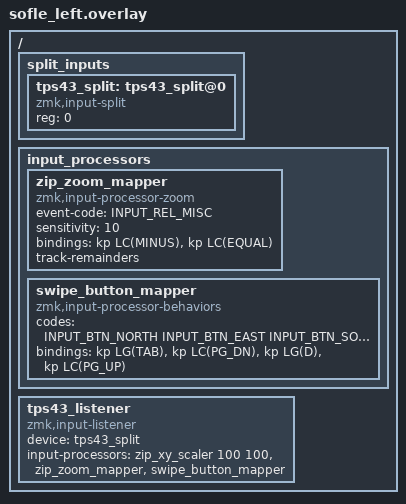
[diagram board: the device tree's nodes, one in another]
/*
 * Central-side (left) half of the Azoteq TPS43 trackpad support.
 *
 * The trackpad itself lives on the right (peripheral) half - see
 * sofle_right.overlay. Its raw input events are relayed over the split
 * link via zmk,input-split; this file is the central-side proxy plus
 * the listener that turns those events into mouse movement, scroll,
 * pinch-zoom and swipe behaviors.
 */

#include <input/processors.dtsi>
#include <dt-bindings/input/input-event-codes.h>
#include <dt-bindings/zmk/keys.h>
#include <behaviors.dtsi>

// Comment out for macOS-style shortcuts (Cmd), leave defined for
// Windows/Linux-style shortcuts (Ctrl).
#define TRACKPAD_WIN_MODE

/ {
    split_inputs {
        #address-cells = <1>;
        #size-cells = <0>;

        tps43_split: tps43_split@0 {
            compatible = "zmk,input-split";
            reg = <0>;
            /* No `device` here - the trackpad lives on the peripheral
             * (right) half; this node is just the central-side proxy
             * that receives its relayed events. */
        };
    };

    input_processors {
        zip_zoom_mapper: zip_zoom_mapper {
            compatible = "zmk,input-processor-zoom";
            #input-processor-cells = <0>;
            event-code = <INPUT_REL_MISC>;
            sensitivity = <10>;
#ifdef TRACKPAD_WIN_MODE
            bindings = <&kp LC(MINUS)>, <&kp LC(EQUAL)>;
#else
            bindings = <&kp LG(MINUS)>, <&kp LG(EQUAL)>;
#endif
            track-remainders;
        };

        swipe_button_mapper: swipe_button_mapper {
            compatible = "zmk,input-processor-behaviors";
            #input-processor-cells = <0>;
            codes = <INPUT_BTN_NORTH INPUT_BTN_EAST INPUT_BTN_SOUTH INPUT_BTN_WEST>;
#ifdef TRACKPAD_WIN_MODE
            bindings = <&kp LG(TAB)>, <&kp LC(PG_DN)>, <&kp LG(D)>, <&kp LC(PG_UP)>;
#else
            bindings = <&kp LC(LG(UP))>, <&kp LC(LG(RIGHT))>, <&kp LC(LG(DOWN))>, <&kp LC(LG(LEFT))>;
#endif
        };
    };

    tps43_listener: tps43_listener {
        compatible = "zmk,input-listener";
        status = "okay";
        device = <&tps43_split>;
        input-processors = <&zip_xy_scaler 100 100>, <&zip_zoom_mapper>, <&swipe_button_mapper>;
    };
};
